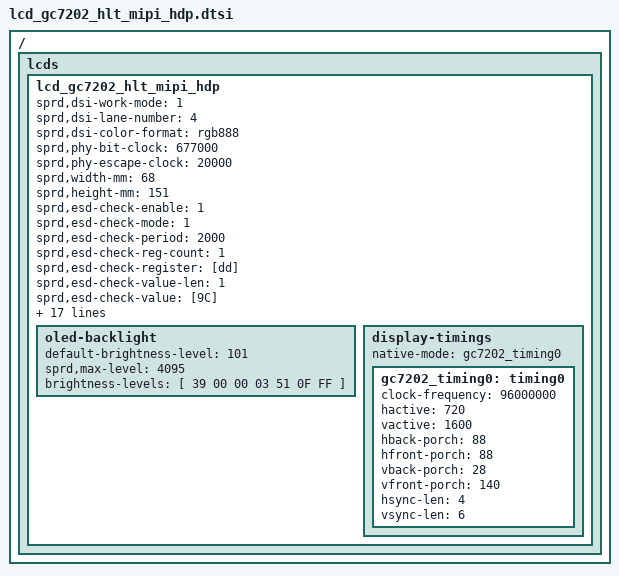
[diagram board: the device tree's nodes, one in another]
/ {
	fragment {
		target-path = "/";
		__overlay__ {
				lcds {
					lcd_gc7202_hlt_mipi_hdp: lcd_gc7202_hlt_mipi_hdp {

						sprd,dsi-work-mode = <1>; /* 1:video burst mode  2:pluse mode*/
						sprd,dsi-lane-number = <4>;
						sprd,dsi-color-format = "rgb888";

						sprd,phy-bit-clock = <677000>;	/* kbps */
						sprd,phy-escape-clock = <20000>;/* kHz */

						sprd,width-mm = <68>;
						sprd,height-mm = <151>;

						sprd,esd-check-enable = <1>;
						sprd,esd-check-mode = <1>;
						sprd,esd-check-period = <2000>;
						sprd,esd-check-reg-count = <1>;
						sprd,esd-check-register = [dd];
						sprd,esd-check-value-len = <1>;
						sprd,esd-check-value = [9C];

						sprd,reset-on-sequence = <1 5>, <0 10>, <1 10>, <0 10>, <1 10>, <0 10>, <1 10>, <0 10>, <1 25>;
						sprd,reset-off-sequence = <1 70>, <0 10>;

						sprd,use-dcs-write;
						sprd,bta-enable = <0>; //move to TP driver
						sprd,bta-check-register = <0xdd>;

						sprd,initial-command = [
							29 00 00 04 FF 55 AA 66
							29 00 00 02 FF 20
							29 00 00 02 FB 00
							29 00 00 02 FF 21
							29 00 00 02 FB 00
							29 00 00 02 FF 22
							29 00 00 02 FB 00
							29 00 00 02 FF 23
							29 00 00 02 FB 00
							29 00 00 02 FF 24
							29 00 00 02 FB 00
							29 00 00 02 FF 26
							29 00 00 02 FB 00
							29 00 00 02 FF 27
							29 00 00 02 FB 00
							29 00 00 02 FF A3
							29 00 00 02 FB 00
							29 00 00 02 FF B3
							29 00 00 02 FB 00
							29 00 00 02 FF C3
							29 00 00 02 FB 00

							29 00 00 02 FF 22
							29 00 00 02 E4 01
							29 00 00 02 01 06
							29 00 00 02 02 40
							29 00 00 02 25 08
							29 00 00 02 26 00
							29 00 00 02 2E 6F
							29 00 00 02 2F 00
							29 00 00 02 36 09
							29 00 00 02 37 00
							29 00 00 02 3F 6F
							29 00 00 02 40 00
							29 00 00 02 0E 33
							29 00 00 02 DC 00
							29 00 00 02 08 40

							29 00 00 02 FF 21
							29 00 00 02 01 25
							29 00 00 02 02 05
							29 00 00 02 03 1A
							29 00 00 02 04 25
							29 00 00 02 05 25
							29 00 00 02 06 01
							29 00 00 02 07 0F
							29 00 00 02 08 0D
							29 00 00 02 09 0B
							29 00 00 02 0A 09
							29 00 00 02 0B 23
							29 00 00 02 0C 23
							29 00 00 02 0D 25
							29 00 00 02 0E 25
							29 00 00 02 0F 25
							29 00 00 02 10 25
							29 00 00 02 11 25
							29 00 00 02 12 25
							29 00 00 02 13 25
							29 00 00 02 14 25
							29 00 00 02 15 25
							29 00 00 02 16 25
							29 00 00 02 17 25
							29 00 00 02 18 04
							29 00 00 02 19 1A
							29 00 00 02 1A 25
							29 00 00 02 1B 25
							29 00 00 02 1C 00
							29 00 00 02 1D 0E
							29 00 00 02 1E 0C
							29 00 00 02 1F 0A
							29 00 00 02 20 08
							29 00 00 02 21 23
							29 00 00 02 22 23
							29 00 00 02 23 25
							29 00 00 02 24 25
							29 00 00 02 25 25
							29 00 00 02 26 25
							29 00 00 02 27 25
							29 00 00 02 28 25
							29 00 00 02 29 25
							29 00 00 02 2A 25
							29 00 00 02 2B 25
							29 00 00 02 2D 25

							29 00 00 02 2E 00
							29 00 00 02 88 A7
							29 00 00 02 89 20
							29 00 00 02 8A 33
							29 00 00 02 94 A7
							29 00 00 02 95 20
							29 00 00 02 96 33
							29 00 00 02 45 33
							29 00 00 02 46 53
							29 00 00 02 47 02
							29 00 00 02 48 01
							29 00 00 02 4C 53
							29 00 00 02 4D 01
							29 00 00 02 4E 02
							29 00 00 02 5E 41
							29 00 00 02 5F 21
							29 00 00 02 60 22
							29 00 00 02 64 41
							29 00 00 02 65 22
							29 00 00 02 66 21
							29 00 00 02 7E 03
							29 00 00 02 7F 21
							29 00 00 02 80 01
							29 00 00 02 81 1A
							29 00 00 02 82 50
							29 00 00 02 83 04
							29 00 00 02 87 00
							29 00 00 02 8B 21
							29 00 00 02 8C 1A
							29 00 00 02 8D 01
							29 00 00 02 8E 50
							29 00 00 02 8F 04
							29 00 00 02 93 00
							29 00 00 02 76 40
							29 00 00 02 77 40
							29 00 00 02 7A 44
							29 00 00 02 7B 44
							29 00 00 02 AF 40
							29 00 00 02 B0 40
							29 00 00 02 C2 85
							29 00 00 02 C6 56
							29 00 00 02 D1 13
							29 00 00 02 49 55
							29 00 00 02 4A 55
							29 00 00 02 4F 55
							29 00 00 02 50 55
							29 00 00 02 61 55
							29 00 00 02 62 55
							29 00 00 02 67 55
							29 00 00 02 68 55
							29 00 00 02 84 55
							29 00 00 02 85 55
							29 00 00 02 90 55
							29 00 00 02 91 55

							29 00 00 02 FF B3
							29 00 00 02 4A 00
							29 00 00 02 7D 28
							29 00 00 02 5B 00
							29 00 00 02 48 23
							29 00 00 02 7C 88
							29 00 00 02 3E 03
							29 00 00 02 82 10
							29 00 00 02 3F 3f
							29 00 00 02 5E 10
							29 00 00 02 58 84
							29 00 00 02 53 1A

							29 00 00 02 FF 20
							29 00 00 02 29 01
							29 00 00 02 2D 1F
							29 00 00 02 02 2B
							29 00 00 02 03 2B
							29 00 00 02 04 45
							29 00 00 02 05 45
							29 00 00 02 0A 1B
							29 00 00 02 0B 1B
							29 00 00 02 0C 4B
							29 00 00 02 0D 4B
							29 00 00 02 77 74
							29 00 00 02 78 74
						//	29 00 00 02 1C 28  //vcom
						//	29 00 00 02 1D 28  //vcom
							29 00 00 02 A5 00
							29 00 00 02 A6 FF
							29 00 00 02 A9 00
							29 00 00 02 AA FF
							29 00 00 02 AD 00
							29 00 00 02 AE FF
							29 00 00 02 B1 00
							29 00 00 02 B2 FF
							29 00 00 02 C3 00
							29 00 00 02 C4 5F
							29 00 00 02 C5 00
							29 00 00 02 C6 5F
							29 00 00 02 B3 00
							29 00 00 02 B4 20
							29 00 00 02 B5 00
							29 00 00 02 B6 DC
							29 00 00 02 C7 00
							29 00 00 02 C8 93
							29 00 00 02 C9 00
							29 00 00 02 CA 93
							29 00 00 02 B7 00
							29 00 00 02 B8 20
							29 00 00 02 B9 01
							29 00 00 02 BA 90
							29 00 00 02 CB 00
							29 00 00 02 CC 90
							29 00 00 02 BB 00
							29 00 00 02 BC 16
							29 00 00 02 BD 00
							29 00 00 02 BE 12
							29 00 00 02 D5 0E
							29 00 00 02 7E 01
							29 00 00 02 7F 00
							29 00 00 02 80 01
							29 00 00 02 81 00
							29 00 00 02 82 00
							29 00 00 02 83 04
							29 00 00 02 84 04
							29 00 00 02 85 01
							29 00 00 02 86 8B
							29 00 00 02 87 01
							29 00 00 02 88 8B
							29 00 00 02 8A 03
							29 00 00 02 8B 03
							29 00 00 02 18 44
							29 00 00 02 17 51
							29 00 00 02 12 A1
							29 00 00 02 15 4C
							29 00 00 02 A3 44
							29 00 00 02 A7 44
							29 00 00 02 D3 03
							29 00 00 02 24 99
							29 00 00 02 25 06
							29 00 00 02 50 00
							29 00 00 02 51 22

							29 00 00 02 FF 23
							29 00 00 11 01 00 00 00 2E 00 5D 00 7D 00 95 00 AA 00 C0 00 CF
							29 00 00 11 02 00 DF 01 0D 01 30 01 61 01 82 01 B4 01 DE 01 DF
							29 00 00 11 03 02 0B 02 43 02 6B 02 A0 02 C4 02 F6 03 06 03 18
							29 00 00 0D 04 03 2C 03 44 03 61 03 88 03 C5 03 FF
							29 00 00 11 05 00 00 00 2E 00 5D 00 7D 00 95 00 AA 00 C0 00 CF
							29 00 00 11 06 00 DF 01 0D 01 30 01 61 01 82 01 B4 01 DE 01 DF
							29 00 00 11 07 02 0B 02 43 02 6B 02 A0 02 C4 02 F6 03 06 03 18
							29 00 00 0D 08 03 2C 03 44 03 61 03 88 03 C5 03 FF
							29 00 00 11 09 00 00 00 2E 00 5D 00 7D 00 95 00 AA 00 C0 00 CF
							29 00 00 11 0A 00 DF 01 0D 01 30 01 61 01 82 01 B4 01 DE 01 DF
							29 00 00 11 0B 02 0B 02 43 02 6B 02 A0 02 C4 02 F6 03 06 03 18
							29 00 00 0D 0C 03 2C 03 44 03 61 03 88 03 C5 03 FF
							29 00 00 11 0D 00 00 00 2E 00 5D 00 7D 00 95 00 AA 00 C0 00 CF
							29 00 00 11 0E 00 DF 01 0D 01 30 01 61 01 82 01 B4 01 DE 01 DF
							29 00 00 11 0F 02 0B 02 43 02 6B 02 A0 02 C4 02 F6 03 06 03 18
							29 00 00 0D 10 03 2C 03 44 03 61 03 88 03 C5 03 FF
							29 00 00 11 11 00 00 00 2E 00 5D 00 7D 00 95 00 AA 00 C0 00 CF
							29 00 00 11 12 00 DF 01 0D 01 30 01 61 01 82 01 B4 01 DE 01 DF
							29 00 00 11 13 02 0B 02 43 02 6B 02 A0 02 C4 02 F6 03 06 03 18
							29 00 00 0D 14 03 2C 03 44 03 61 03 88 03 C5 03 FF
							29 00 00 11 15 00 00 00 2E 00 5D 00 7D 00 95 00 AA 00 C0 00 CF
							29 00 00 11 16 00 DF 01 0D 01 30 01 61 01 82 01 B4 01 DE 01 DF
							29 00 00 11 17 02 0B 02 43 02 6B 02 A0 02 C4 02 F6 03 06 03 18
							29 00 00 0D 18 03 2C 03 44 03 61 03 88 03 C5 03 FF
							29 00 00 02 2D 65
							29 00 00 02 37 01
							29 00 00 02 2E 00
							29 00 00 02 32 00
							29 00 00 02 33 18
							29 00 00 02 B9 31
							29 00 00 02 B8 b7
							29 00 00 02 35 16
							29 00 00 02 36 0C
							29 00 00 02 30 00
							29 00 00 11 1F 0a 00 20 00 44 00 70 00 A8 00 e6 00 0a 00 20 00
							29 00 00 09 20 44 00 70 00 A8 00 FF 00
							29 00 00 11 21 a7 00 b2 00 c0 00 cd 00 dA 00 f3 00 D8 00 D8 00
							29 00 00 09 22 d8 00 d8 00 d8 00 ff 00
							29 00 00 11 23 00 00 00 00 00 00 00 00 00 00 00 00 00 00 00 00
							29 00 00 09 24 00 00 00 00 00 00 00 00
							29 00 00 02 FF 26
							29 00 00 05 1D 0C 00 00 00

							29 00 00 02 FF 24
							29 00 00 03 03 01 dd
							29 00 00 02 50 aa
							29 00 00 02 FF 22
							29 00 00 02 1F 06

							29 00 00 02 FF A3
							29 00 00 02 FA 01
							29 00 00 02 35 00
							29 00 00 02 45 10
							29 00 00 02 05 05
							29 00 00 02 FF 10
							29 00 00 03 51 00 00
							29 00 00 02 53 2C
							29 00 00 02 55 01
							29 00 00 02 36 08
							29 00 00 02 69 00
							29 00 00 02 35 00
							05 78 00 01 11
							05 78 00 01 29
						];

						sprd,sleep-in-command = [
							39 00 00 04 FF 55 AA 66
							15 00 00 02 FF 20
							15 00 00 02 4A 01
							15 00 00 02 48 10
							15 00 00 02 49 00
							15 00 00 02 FF 21
							15 00 00 02 FB 00
							15 00 00 02 D1 00
							15 00 00 02 FF 10
							05 64 00 01 28
							05 78 00 01 10
							39 00 00 04 FF 55 AA 66
							15 00 00 02 FF 26
							15 00 00 02 FB 00
							39 00 00 05 1D A2 AA AA 0A
							15 00 00 02 FF 10
							15 00 00 02 FB 00
							15 00 00 02 4F 01
						];//gesture off

						sprd,sleep-gesture-command = [
							39 00 00 04 FF 55 AA 66
							15 00 00 02 FF 20
							15 00 00 02 4A 01
							15 00 00 02 48 10
							15 00 00 02 49 00
							15 00 00 02 FF 21
							15 00 00 02 FB 00
							15 00 00 02 D1 00
							15 00 00 02 FF 10
							05 64 00 01 28
							05 78 00 01 10
						];//gesture on

						sprd,sleep-out-command = [
							05 78 00 01 11
							05 23 00 01 29
						];

						sprd,cabc-ui-mode = [
							15 00 00 02 55 01
						];

						sprd,cabc-mov-mode = [
							15 00 00 02 55 03
						];

						sprd,cabc-off-mode = [
							15 00 00 02 55 02
						];

						oled-backlight {
							default-brightness-level = <101>;
							sprd,max-level = <4095>;
							brightness-levels = [
								39 00 00 03 51 0F FF
							];
						};
						display-timings {
							native-mode = <&gc7202_timing0>;

							gc7202_timing0: timing0 {
								clock-frequency = <96000000>;
								hactive = <720>;
								vactive = <1600>;
								hback-porch = <88>;
								hfront-porch = <88>;
								vback-porch = <28>;
								vfront-porch = <140>;
								hsync-len = <4>;
								vsync-len = <6>;
							};
						};
					};
				};
		};
	};
};

